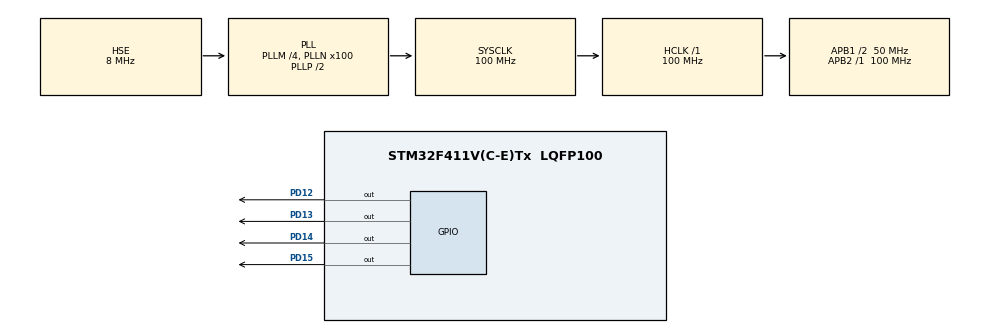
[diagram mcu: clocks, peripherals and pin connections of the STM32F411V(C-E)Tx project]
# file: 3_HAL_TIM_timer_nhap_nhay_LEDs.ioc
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Mcu.Family=STM32F4
RCC.PLLSourceVirtual=RCC_PLLSOURCE_HSE
RCC.CortexFreq_Value=100000000
PD12.GPIO_Speed=GPIO_SPEED_FREQ_HIGH
PD15.GPIO_Speed=GPIO_SPEED_FREQ_HIGH
PH1\ -\ OSC_OUT.Mode=HSE-External-Oscillator
RCC.APB1CLKDivider=RCC_HCLK_DIV2
RCC.SYSCLKSource=RCC_SYSCLKSOURCE_PLLCLK
ProjectManager.StackSize=0x400
PA13.Signal=SYS_JTMS-SWDIO
PD13.Signal=GPIO_Output
PD14.GPIO_Speed=GPIO_SPEED_FREQ_HIGH
PH0\ -\ OSC_IN.Mode=HSE-External-Oscillator
PH0\ -\ OSC_IN.Signal=RCC_OSC_IN
ProjectManager.TargetToolchain=STM32CubeIDE
RCC.HCLKFreq_Value=100000000
RCC.APB2TimFreq_Value=100000000
RCC.LSE_VALUE=32768
RCC.AHBFreq_Value=100000000
RCC.HSE_VALUE=8000000
PH1\ -\ OSC_OUT.Signal=RCC_OSC_OUT
board=custom
PD13.GPIO_Speed=GPIO_SPEED_FREQ_HIGH
RCC.VCOOutputFreq_Value=200000000
RCC.APB2Freq_Value=100000000
VP_TIM2_VS_ClockSourceINT.Mode=Internal
PA14.Mode=Serial_Wire
NVIC.TIM2_IRQn=true\:0\:0\:false\:false\:true\:true\:true
TIM2.Period=2000-1
PA13.Mode=Serial_Wire
Mcu.Name=STM32F411V(C-E)Tx
PD14.Signal=GPIO_Output
RCC.48MHZClocksFreq_Value=50000000
RCC.SYSCLKFreq_VALUE=100000000
Mcu.Package=LQFP100
TIM2.Prescaler=50000-1
PD12.Signal=GPIO_Output
PA14.Signal=SYS_JTCK-SWCLK
ProjectManager.HeapSize=0x200
RCC.HSI_VALUE=16000000
NVIC.PriorityGroup=NVIC_PRIORITYGROUP_4
RCC.PLLM=4
RCC.PLLN=100
RCC.APB1TimFreq_Value=100000000
TIM2.AutoReloadPreload=TIM_AUTORELOAD_PRELOAD_DISABLE
RCC.APB1Freq_Value=50000000
PD15.Signal=GPIO_Output

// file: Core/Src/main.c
/* USER CODE BEGIN Header */
/**
  ******************************************************************************
  * @file           : main.c
  * @brief          : Main program body
  ******************************************************************************
  * @attention
  *
  * <h2><center>&copy; Copyright (c) 2022 STMicroelectronics.
  * All rights reserved.</center></h2>
  *
  * This software component is licensed by ST under BSD 3-Clause license,
  * the "License"; You may not use this file except in compliance with the
  * License. You may obtain a copy of the License at:
  *                        opensource.org/licenses/BSD-3-Clause
  *
  ******************************************************************************
  */
/* USER CODE END Header */
#include "main.h"

/* USER CODE BEGIN PTD */
uint8_t dem = 0, level = 0;
/* USER CODE END PTD */

TIM_HandleTypeDef htim2;

void SystemClock_Config(void);
static void MX_GPIO_Init(void);
static void MX_TIM2_Init(void);

int main(void)
{
  HAL_Init();
  SystemClock_Config();

  MX_GPIO_Init();
  MX_TIM2_Init();
  /* USER CODE BEGIN 2 */
  HAL_TIM_Base_Start_IT(&htim2);

  while (1)
  {

  }
  /* USER CODE END 3 */
}

void HAL_TIM_PeriodElapsedCallback(TIM_HandleTypeDef *htim){
	if(htim->Instance == htim2.Instance){
		dem++;
		level = dem % 2;
		HAL_GPIO_TogglePin(GPIOD, GPIO_PIN_12|GPIO_PIN_13|GPIO_PIN_14|GPIO_PIN_15);
		//co HAL_Delay() khong duoc
	}
}
void SystemClock_Config(void)
{
  RCC_OscInitTypeDef RCC_OscInitStruct = {0};
  RCC_ClkInitTypeDef RCC_ClkInitStruct = {0};

  /** Configure the main internal regulator output voltage
  */
  __HAL_RCC_PWR_CLK_ENABLE();
  __HAL_PWR_VOLTAGESCALING_CONFIG(PWR_REGULATOR_VOLTAGE_SCALE1);
  /** Initializes the RCC Oscillators according to the specified parameters
  * in the RCC_OscInitTypeDef structure.
  */
  RCC_OscInitStruct.OscillatorType = RCC_OSCILLATORTYPE_HSE;
  RCC_OscInitStruct.HSEState = RCC_HSE_ON;
  RCC_OscInitStruct.PLL.PLLState = RCC_PLL_ON;
  RCC_OscInitStruct.PLL.PLLSource = RCC_PLLSOURCE_HSE;
  RCC_OscInitStruct.PLL.PLLM = 4;
  RCC_OscInitStruct.PLL.PLLN = 100;
  RCC_OscInitStruct.PLL.PLLP = RCC_PLLP_DIV2;
  RCC_OscInitStruct.PLL.PLLQ = 4;
  if (HAL_RCC_OscConfig(&RCC_OscInitStruct) != HAL_OK)
  {
    Error_Handler();
  }
  /** Initializes the CPU, AHB and APB buses clocks
  */
  RCC_ClkInitStruct.ClockType = RCC_CLOCKTYPE_HCLK|RCC_CLOCKTYPE_SYSCLK
                              |RCC_CLOCKTYPE_PCLK1|RCC_CLOCKTYPE_PCLK2;
  RCC_ClkInitStruct.SYSCLKSource = RCC_SYSCLKSOURCE_PLLCLK;
  RCC_ClkInitStruct.AHBCLKDivider = RCC_SYSCLK_DIV1;
  RCC_ClkInitStruct.APB1CLKDivider = RCC_HCLK_DIV2;
  RCC_ClkInitStruct.APB2CLKDivider = RCC_HCLK_DIV1;

  if (HAL_RCC_ClockConfig(&RCC_ClkInitStruct, FLASH_LATENCY_3) != HAL_OK)
  {
    Error_Handler();
  }
}

static void MX_TIM2_Init(void)
{

  TIM_ClockConfigTypeDef sClockSourceConfig = {0};
  TIM_MasterConfigTypeDef sMasterConfig = {0};

  htim2.Instance = TIM2;
  htim2.Init.Prescaler = 50000-1;
  htim2.Init.CounterMode = TIM_COUNTERMODE_UP;
  htim2.Init.Period = 2000-1;
  htim2.Init.ClockDivision = TIM_CLOCKDIVISION_DIV1;
  htim2.Init.AutoReloadPreload = TIM_AUTORELOAD_PRELOAD_DISABLE;
  if (HAL_TIM_Base_Init(&htim2) != HAL_OK)
  {
    Error_Handler();
  }
  sClockSourceConfig.ClockSource = TIM_CLOCKSOURCE_INTERNAL;
  if (HAL_TIM_ConfigClockSource(&htim2, &sClockSourceConfig) != HAL_OK)
  {
    Error_Handler();
  }
  sMasterConfig.MasterOutputTrigger = TIM_TRGO_RESET;
  sMasterConfig.MasterSlaveMode = TIM_MASTERSLAVEMODE_DISABLE;
  if (HAL_TIMEx_MasterConfigSynchronization(&htim2, &sMasterConfig) != HAL_OK)
  {
    Error_Handler();
  }

}

static void MX_GPIO_Init(void)
{
  GPIO_InitTypeDef GPIO_InitStruct = {0};

  /* GPIO Ports Clock Enable */
  __HAL_RCC_GPIOH_CLK_ENABLE();
  __HAL_RCC_GPIOD_CLK_ENABLE();
  __HAL_RCC_GPIOA_CLK_ENABLE();

  /*Configure GPIO pin Output Level */
  HAL_GPIO_WritePin(GPIOD, GPIO_PIN_12|GPIO_PIN_13|GPIO_PIN_14|GPIO_PIN_15, GPIO_PIN_RESET);

  /*Configure GPIO pins : PD12 PD13 PD14 PD15 */
  GPIO_InitStruct.Pin = GPIO_PIN_12|GPIO_PIN_13|GPIO_PIN_14|GPIO_PIN_15;
  GPIO_InitStruct.Mode = GPIO_MODE_OUTPUT_PP;
  GPIO_InitStruct.Pull = GPIO_NOPULL;
  GPIO_InitStruct.Speed = GPIO_SPEED_FREQ_HIGH;
  HAL_GPIO_Init(GPIOD, &GPIO_InitStruct);

}

void Error_Handler(void)
{
  __disable_irq();
  while (1)
  {
  }
}

/************************ (C) COPYRIGHT STMicroelectronics *****END OF FILE****/
